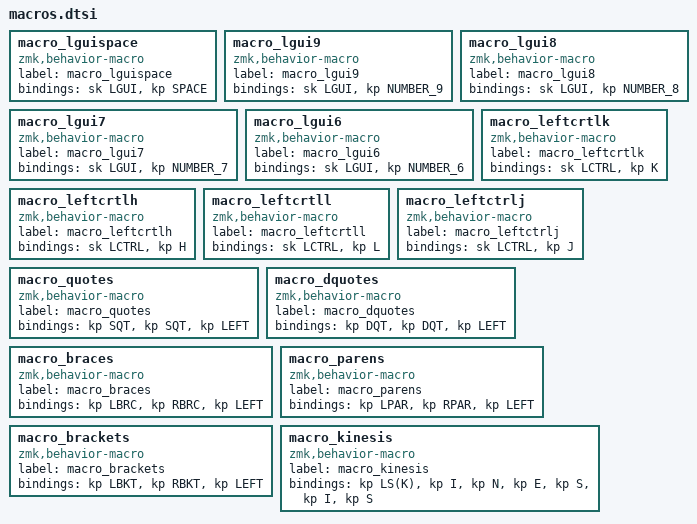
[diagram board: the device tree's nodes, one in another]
macro_lguispace: macro_lguispace{
compatible = "zmk,behavior-macro";
label = "macro_lguispace";
#binding-cells = <0>;
bindings = <&sk LGUI>, <&kp SPACE>;
};
macro_lgui9: macro_lgui9{
compatible = "zmk,behavior-macro";
label = "macro_lgui9";
#binding-cells = <0>;
bindings = <&sk LGUI &kp NUMBER_9>;
};
macro_lgui8: macro_lgui8{
compatible = "zmk,behavior-macro";
label = "macro_lgui8";
#binding-cells = <0>;
bindings = <&sk LGUI &kp NUMBER_8>;
};
macro_lgui7: macro_lgui7{
compatible = "zmk,behavior-macro";
label = "macro_lgui7";
#binding-cells = <0>;
bindings = <&sk LGUI &kp NUMBER_7>;
};
macro_lgui6: macro_lgui6{
compatible = "zmk,behavior-macro";
label = "macro_lgui6";
#binding-cells = <0>;
bindings = <&sk LGUI &kp NUMBER_6>;
};
macro_leftcrtlk: macro_leftcrtlk{
compatible = "zmk,behavior-macro";
label = "macro_leftcrtlk";
#binding-cells = <0>;
bindings = <&sk LCTRL &kp K>;
};
macro_leftcrtlh: macro_leftcrtlh{
compatible = "zmk,behavior-macro";
label = "macro_leftcrtlh";
#binding-cells = <0>;
bindings = <&sk LCTRL &kp H>;
};
macro_leftcrtll: macro_leftcrtll{
compatible = "zmk,behavior-macro";
label = "macro_leftcrtll";
#binding-cells = <0>;
bindings = <&sk LCTRL &kp L>;
};
macro_leftctrlj: macro_leftctrlj{
compatible = "zmk,behavior-macro";
label = "macro_leftctrlj";
#binding-cells = <0>;
bindings = <&sk LCTRL &kp J>;
};
macro_quotes: macro_quotes{
compatible = "zmk,behavior-macro";
label = "macro_quotes";
#binding-cells = <0>;
bindings = <&kp SQT>, <&kp SQT>, <&kp LEFT>;
};
macro_dquotes: macro_dquotes{
compatible = "zmk,behavior-macro";
label = "macro_dquotes";
#binding-cells = <0>;
bindings = <&kp DQT>, <&kp DQT>, <&kp LEFT>;
};
macro_braces: macro_braces{
compatible = "zmk,behavior-macro";
label = "macro_braces";
#binding-cells = <0>;
bindings = <&kp LBRC>, <&kp RBRC>, <&kp LEFT>;
};
macro_parens: macro_parens{
compatible = "zmk,behavior-macro";
label = "macro_parens";
#binding-cells = <0>;
bindings = <&kp LPAR>, <&kp RPAR>, <&kp LEFT>;
};
macro_brackets: macro_brackets{
compatible = "zmk,behavior-macro";
label = "macro_brackets";
#binding-cells = <0>;
bindings = <&kp LBKT>, <&kp RBKT>, <&kp LEFT>;
};
macro_kinesis: macro_kinesis{
compatible = "zmk,behavior-macro";
label = "macro_kinesis";
#binding-cells = <0>;
bindings = <&kp LS(K)>, <&kp I>, <&kp N>, <&kp E>, <&kp S>, <&kp I>, <&kp S>;
};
